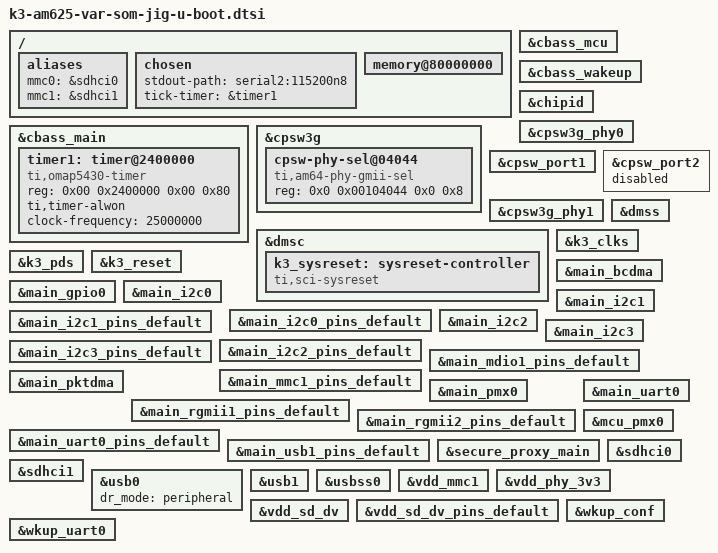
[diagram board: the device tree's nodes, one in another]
// SPDX-License-Identifier: GPL-2.0
/*
 * VAR-SOM-AM62 dts file for SPLs
 * Copyright (C) 2021-2022 Texas Instruments Incorporated - https://www.ti.com/
 * Copyright (C) 2023 Variscite Ltd. - https://www.variscite.com/
 */
#include "k3-am625-var-som-jig-binman.dtsi"
/ {
	aliases {
		mmc0 = &sdhci0;
		mmc1 = &sdhci1;
	};

	chosen {
		stdout-path = "serial2:115200n8";
		tick-timer = &timer1;
	};

	memory@80000000 {
		bootph-pre-ram;
	};
};

&cbass_main{
        bootph-pre-ram;

	timer1: timer@2400000 {
		compatible = "ti,omap5430-timer";
		reg = <0x00 0x2400000 0x00 0x80>;
		ti,timer-alwon;
		clock-frequency = <25000000>;
		bootph-pre-ram;
	};
};

&cbass_mcu {
	bootph-pre-ram;
};

&cbass_wakeup {
	bootph-pre-ram;
};

&chipid {
	bootph-pre-ram;
};

&cpsw3g {
	/delete-property/ ranges;
	bootph-pre-ram;

	cpsw-phy-sel@04044 {
		compatible = "ti,am64-phy-gmii-sel";
		reg = <0x0 0x00104044 0x0 0x8>;
		bootph-pre-ram;
	};
};

&cpsw3g_phy0 {
	bootph-pre-ram;
};

&cpsw_port1 {
	bootph-pre-ram;
};

&cpsw_port2 {
	status = "disabled";
};

&cpsw3g_phy1 {
	bootph-pre-ram;
};

&dmsc {
	bootph-pre-ram;
	k3_sysreset: sysreset-controller {
		compatible = "ti,sci-sysreset";
		bootph-pre-ram;
	};
};

&dmss {
	bootph-pre-ram;
};

&k3_clks {
	bootph-pre-ram;
};

&k3_pds {
	bootph-pre-ram;
};

&k3_reset {
	bootph-pre-ram;
};

&main_bcdma {
	bootph-pre-ram;
};

&main_gpio0 {
	bootph-pre-ram;
};

&main_i2c0 {
	bootph-pre-ram;
};

&main_i2c0_pins_default {
	bootph-pre-ram;
};

&main_i2c1 {
	bootph-pre-ram;
};

&main_i2c1_pins_default {
	bootph-pre-ram;
};

&main_i2c2 {
	bootph-pre-ram;
};

&main_i2c2_pins_default {
	bootph-pre-ram;
};

&main_i2c3 {
	bootph-pre-ram;
	/delete-property/ power-domains;
};

&main_i2c3_pins_default {
	bootph-pre-ram;
};

&main_mdio1_pins_default {
	bootph-pre-ram;
};

&main_mmc1_pins_default {
	bootph-pre-ram;
};

&main_pktdma {
	bootph-pre-ram;
};

&main_pmx0 {
	bootph-pre-ram;
};

&main_rgmii1_pins_default {
	bootph-pre-ram;
};

&main_rgmii2_pins_default {
	bootph-pre-ram;
};

&main_uart0 {
	bootph-pre-ram;
};

&main_uart0_pins_default {
	bootph-pre-ram;
};

&main_usb1_pins_default {
	bootph-pre-ram;
};

&mcu_pmx0 {
	bootph-pre-ram;
};

&secure_proxy_main {
	bootph-pre-ram;
};

&sdhci0 {
	bootph-pre-ram;
};

&sdhci1 {
	bootph-pre-ram;
};

&usb0 {
	dr_mode = "peripheral";
	/* Since role switching is not supported in U-Boot */
	/delete-property/ extcon;
	bootph-pre-ram;
};

&usb1 {
	bootph-pre-ram;
};

&usbss0 {
	bootph-pre-ram;
};

&vdd_mmc1 {
	bootph-pre-ram;
};

&vdd_phy_3v3 {
	bootph-pre-ram;
};

&vdd_sd_dv {
	bootph-pre-ram;
};

&vdd_sd_dv_pins_default {
	bootph-pre-ram;
};

&wkup_conf {
	bootph-pre-ram;
};

&wkup_uart0 {
	bootph-pre-ram;
};
